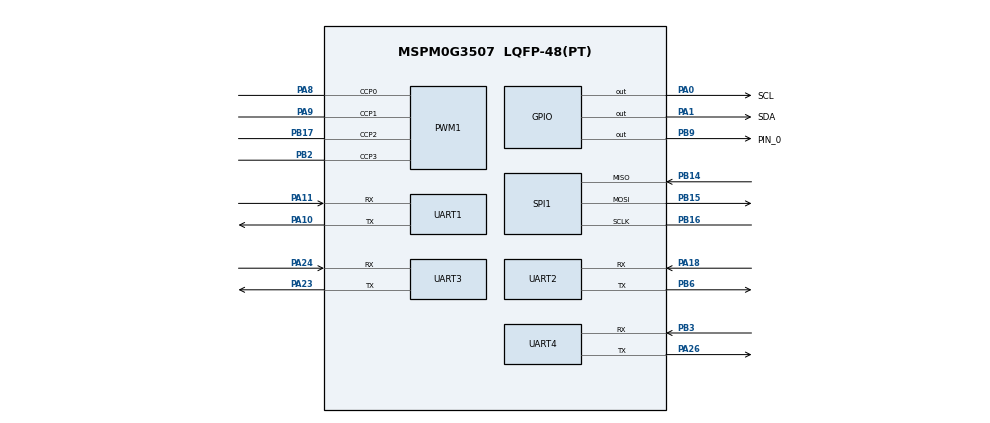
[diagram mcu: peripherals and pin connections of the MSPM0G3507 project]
/**
 * These arguments were used when this file was generated. They will be automatically applied on subsequent loads
 * via the GUI or CLI. Run CLI with '--help' for additional information on how to override these arguments.
 * @cliArgs --device "MSPM0G350X" --part "Default" --package "LQFP-48(PT)" --product "mspm0_sdk@2.10.00.04"
 * @v2CliArgs --device "MSPM0G3507" --package "LQFP-48(PT)" --product "mspm0_sdk@2.10.00.04"
 * @versions {"tool":"1.26.2+4477"}
 */

/**
 * Import the modules used in this configuration.
 */
const GPIO   = scripting.addModule("/ti/driverlib/GPIO", {}, false);
const GPIO1  = GPIO.addInstance();
const GPIO2  = GPIO.addInstance();
const GPIO3  = GPIO.addInstance();
const PWM    = scripting.addModule("/ti/driverlib/PWM", {}, false);
const PWM1   = PWM.addInstance();
const SPI    = scripting.addModule("/ti/driverlib/SPI", {}, false);
const SPI1   = SPI.addInstance();
const SYSCTL = scripting.addModule("/ti/driverlib/SYSCTL");
const TIMER  = scripting.addModule("/ti/driverlib/TIMER", {}, false);
const TIMER1 = TIMER.addInstance();
const UART   = scripting.addModule("/ti/driverlib/UART", {}, false);
const UART1  = UART.addInstance();
const UART2  = UART.addInstance();
const UART3  = UART.addInstance();
const UART4  = UART.addInstance();

/**
 * Write custom configuration values to the imported modules.
 */
const divider9       = system.clockTree["UDIV"];
divider9.divideValue = 2;

const gate7  = system.clockTree["MFCLKGATE"];
gate7.enable = true;

const multiplier2         = system.clockTree["PLL_QDIV"];
multiplier2.multiplyValue = 5;

const mux2       = system.clockTree["CANCLKMUX"];
mux2.inputSelect = "CANCLKMUX_PLLCLK1_OUT";

const mux4       = system.clockTree["EXHFMUX"];
mux4.inputSelect = "EXHFMUX_XTAL";

const mux8       = system.clockTree["HSCLKMUX"];
mux8.inputSelect = "HSCLKMUX_SYSPLL0";

const mux10       = system.clockTree["MFPCLKMUX"];
mux10.inputSelect = "MFPCLKMUX_HFCLK";

const pinFunction4       = system.clockTree["HFXT"];
pinFunction4.HFXTStartup = 10;
pinFunction4.enable      = true;
pinFunction4.inputFreq   = 8;

GPIO1.$name                              = "LED";
GPIO1.port                               = "PORTA";
GPIO1.associatedPins[0].internalResistor = "PULL_DOWN";
GPIO1.associatedPins[0].$name            = "A27";
GPIO1.associatedPins[0].assignedPin      = "27";

const Board = scripting.addModule("/ti/driverlib/Board", {}, false);

GPIO2.$name                              = "IIC";
GPIO2.associatedPins.create(2);
GPIO2.associatedPins[0].$name            = "SCL";
GPIO2.associatedPins[0].internalResistor = "PULL_UP";
GPIO2.associatedPins[0].initialValue     = "SET";
GPIO2.associatedPins[0].ioStructure      = "OD";
GPIO2.associatedPins[0].pin.$assign      = "PA0";
GPIO2.associatedPins[1].$name            = "SDA";
GPIO2.associatedPins[1].internalResistor = "PULL_UP";
GPIO2.associatedPins[1].initialValue     = "SET";
GPIO2.associatedPins[1].ioStructure      = "OD";
GPIO2.associatedPins[1].pin.$assign      = "PA1";

GPIO3.$name                          = "spi_cs";
GPIO3.associatedPins[0].$name        = "PIN_0";
GPIO3.associatedPins[0].assignedPort = "PORTB";
GPIO3.associatedPins[0].pin.$assign  = "PB9";

PWM1.$name                              = "PWM_MOTOR";
PWM1.timerStartTimer                    = true;
PWM1.ccIndex                            = [0,1,2,3];
PWM1.clockDivider                       = 4;
PWM1.pwmMode                            = "EDGE_ALIGN_UP";
PWM1.interrupts                         = ["LOAD_EVENT"];
PWM1.PWM_CHANNEL_0.$name                = "ti_driverlib_pwm_PWMTimerCC0";
PWM1.PWM_CHANNEL_0.dutyCycle            = 50;
PWM1.PWM_CHANNEL_1.$name                = "ti_driverlib_pwm_PWMTimerCC1";
PWM1.PWM_CHANNEL_1.dutyCycle            = 50;
PWM1.ccp0PinConfig.direction            = scripting.forceWrite("OUTPUT");
PWM1.ccp0PinConfig.hideOutputInversion  = scripting.forceWrite(false);
PWM1.ccp0PinConfig.onlyInternalResistor = scripting.forceWrite(false);
PWM1.ccp0PinConfig.passedPeripheralType = scripting.forceWrite("Digital");
PWM1.ccp0PinConfig.$name                = "ti_driverlib_gpio_GPIOPinGeneric2";
PWM1.ccp1PinConfig.direction            = scripting.forceWrite("OUTPUT");
PWM1.ccp1PinConfig.hideOutputInversion  = scripting.forceWrite(false);
PWM1.ccp1PinConfig.onlyInternalResistor = scripting.forceWrite(false);
PWM1.ccp1PinConfig.passedPeripheralType = scripting.forceWrite("Digital");
PWM1.ccp1PinConfig.$name                = "ti_driverlib_gpio_GPIOPinGeneric3";
PWM1.peripheral.$assign                 = "TIMA0";
PWM1.peripheral.ccp0Pin.$assign         = "PA8";
PWM1.peripheral.ccp1Pin.$assign         = "PA9";
PWM1.peripheral.ccp2Pin.$assign         = "PB17";
PWM1.peripheral.ccp3Pin.$assign         = "PB2";
PWM1.PWM_CHANNEL_2.$name                = "ti_driverlib_pwm_PWMTimerCC2";
PWM1.PWM_CHANNEL_2.dutyCycle            = 50;
PWM1.PWM_CHANNEL_3.$name                = "ti_driverlib_pwm_PWMTimerCC3";
PWM1.PWM_CHANNEL_3.dutyCycle            = 50;
PWM1.ccp2PinConfig.$name                = "ti_driverlib_gpio_GPIOPinGeneric5";
PWM1.ccp3PinConfig.$name                = "ti_driverlib_gpio_GPIOPinGeneric6";

SPI1.$name                                   = "SPI_0";
SPI1.peripheral.$assign                      = "SPI1";
SPI1.peripheral.sclkPin.$assign              = "PB16";
SPI1.peripheral.mosiPin.$assign              = "PB15";
SPI1.peripheral.misoPin.$assign              = "PB14";
SPI1.peripheral.cs0Pin.$assignAllowConflicts = "PA2";
SPI1.sclkPinConfig.$name                     = "ti_driverlib_gpio_GPIOPinGeneric10";
SPI1.mosiPinConfig.$name                     = "ti_driverlib_gpio_GPIOPinGeneric12";
SPI1.misoPinConfig.$name                     = "ti_driverlib_gpio_GPIOPinGeneric13";
SPI1.cs0PinConfig.$name                      = "ti_driverlib_gpio_GPIOPinGeneric14";

SYSCTL.forceDefaultClkConfig = true;
SYSCTL.clockTreeEn           = true;
SYSCTL.validateClkStatus     = true;

TIMER1.$name             = "TIMER_0";
TIMER1.interruptPriority = "3";
TIMER1.timerClkDiv       = 8;
TIMER1.timerClkPrescale  = 10;
TIMER1.timerPeriod       = "65.536ms";
TIMER1.timerMode         = "PERIODIC_UP";
TIMER1.interrupts        = ["LOAD"];

UART1.interruptPriority                = "3";
UART1.targetBaudRate                   = 115200;
UART1.$name                            = "UART_0_DEBUG";
UART1.enableFIFO                       = true;
UART1.enabledDMATXTriggers             = "DL_UART_DMA_INTERRUPT_TX";
UART1.rxFifoThreshold                  = "DL_UART_RX_FIFO_LEVEL_ONE_ENTRY";
UART1.enabledInterrupts                = ["DMA_DONE_TX","EOT_DONE","RX","RX_TIMEOUT_ERROR"];
UART1.enableDMARX                      = false;
UART1.rxTimeoutValue                   = 10;
UART1.peripheral.$assign               = "UART0";
UART1.peripheral.rxPin.$assign         = "PA11";
UART1.peripheral.txPin.$assign         = "PA10";
UART1.txPinConfig.direction            = scripting.forceWrite("OUTPUT");
UART1.txPinConfig.hideOutputInversion  = scripting.forceWrite(false);
UART1.txPinConfig.onlyInternalResistor = scripting.forceWrite(false);
UART1.txPinConfig.passedPeripheralType = scripting.forceWrite("Digital");
UART1.txPinConfig.$name                = "ti_driverlib_gpio_GPIOPinGeneric0";
UART1.rxPinConfig.hideOutputInversion  = scripting.forceWrite(false);
UART1.rxPinConfig.onlyInternalResistor = scripting.forceWrite(false);
UART1.rxPinConfig.passedPeripheralType = scripting.forceWrite("Digital");
UART1.rxPinConfig.$name                = "ti_driverlib_gpio_GPIOPinGeneric1";
UART1.DMA_CHANNEL_TX.$name             = "DMA_CH1";
UART1.DMA_CHANNEL_TX.srcLength         = "BYTE";
UART1.DMA_CHANNEL_TX.dstLength         = "BYTE";
UART1.DMA_CHANNEL_TX.addressMode       = "b2f";
UART1.DMA_CHANNEL_TX.enableInterrupt   = true;

UART2.targetBaudRate                    = 115200;
UART2.$name                             = "UART1";
UART2.enableFIFO                        = true;
UART2.rxFifoThreshold                   = "DL_UART_RX_FIFO_LEVEL_ONE_ENTRY";
UART2.rxTimeoutValue                    = 10;
UART2.enabledInterrupts                 = ["DMA_DONE_TX","EOT_DONE","RX"];
UART2.interruptPriority                 = "3";
UART2.enabledDMATXTriggers              = "DL_UART_DMA_INTERRUPT_TX";
UART2.peripheral.$assign                = "UART1";
UART2.peripheral.rxPin.$assign          = "PA18";
UART2.peripheral.txPin.$assign          = "PB6";
UART2.txPinConfig.direction             = scripting.forceWrite("OUTPUT");
UART2.txPinConfig.hideOutputInversion   = scripting.forceWrite(false);
UART2.txPinConfig.onlyInternalResistor  = scripting.forceWrite(false);
UART2.txPinConfig.passedPeripheralType  = scripting.forceWrite("Digital");
UART2.txPinConfig.$name                 = "ti_driverlib_gpio_GPIOPinGeneric19";
UART2.rxPinConfig.hideOutputInversion   = scripting.forceWrite(false);
UART2.rxPinConfig.onlyInternalResistor  = scripting.forceWrite(false);
UART2.rxPinConfig.passedPeripheralType  = scripting.forceWrite("Digital");
UART2.rxPinConfig.$name                 = "ti_driverlib_gpio_GPIOPinGeneric20";
UART2.DMA_CHANNEL_TX.$name              = "DMA_CH0";
UART2.DMA_CHANNEL_TX.addressMode        = "b2f";
UART2.DMA_CHANNEL_TX.srcLength          = "BYTE";
UART2.DMA_CHANNEL_TX.dstLength          = "BYTE";
UART2.DMA_CHANNEL_TX.enableInterrupt    = true;
UART2.DMA_CHANNEL_TX.peripheral.$assign = "DMA_CH1";

UART3.$name                             = "UART2";
UART3.enableFIFO                        = true;
UART3.rxFifoThreshold                   = "DL_UART_RX_FIFO_LEVEL_ONE_ENTRY";
UART3.rxTimeoutValue                    = 10;
UART3.enabledInterrupts                 = ["DMA_DONE_TX","EOT_DONE","RX"];
UART3.enabledDMATXTriggers              = "DL_UART_DMA_INTERRUPT_TX";
UART3.peripheral.rxPin.$assign          = "PA24";
UART3.peripheral.txPin.$assign          = "PA23";
UART3.txPinConfig.$name                 = "ti_driverlib_gpio_GPIOPinGeneric4";
UART3.txPinConfig.direction             = scripting.forceWrite("OUTPUT");
UART3.txPinConfig.hideOutputInversion   = scripting.forceWrite(false);
UART3.txPinConfig.onlyInternalResistor  = scripting.forceWrite(false);
UART3.txPinConfig.passedPeripheralType  = scripting.forceWrite("Digital");
UART3.rxPinConfig.$name                 = "ti_driverlib_gpio_GPIOPinGeneric7";
UART3.rxPinConfig.hideOutputInversion   = scripting.forceWrite(false);
UART3.rxPinConfig.onlyInternalResistor  = scripting.forceWrite(false);
UART3.rxPinConfig.passedPeripheralType  = scripting.forceWrite("Digital");
UART3.DMA_CHANNEL_TX.$name              = "DMA_CH2";
UART3.DMA_CHANNEL_TX.addressMode        = "b2f";
UART3.DMA_CHANNEL_TX.srcLength          = "BYTE";
UART3.DMA_CHANNEL_TX.dstLength          = "BYTE";
UART3.DMA_CHANNEL_TX.enableInterrupt    = true;
UART3.DMA_CHANNEL_TX.peripheral.$assign = "DMA_CH2";

UART4.$name                             = "UART3";
UART4.enabledDMATXTriggers              = "DL_UART_DMA_INTERRUPT_TX";
UART4.peripheral.rxPin.$assign          = "PB3";
UART4.peripheral.txPin.$assign          = "PA26";
UART4.txPinConfig.$name                 = "ti_driverlib_gpio_GPIOPinGeneric8";
UART4.txPinConfig.direction             = scripting.forceWrite("OUTPUT");
UART4.txPinConfig.hideOutputInversion   = scripting.forceWrite(false);
UART4.txPinConfig.onlyInternalResistor  = scripting.forceWrite(false);
UART4.txPinConfig.passedPeripheralType  = scripting.forceWrite("Digital");
UART4.rxPinConfig.$name                 = "ti_driverlib_gpio_GPIOPinGeneric9";
UART4.rxPinConfig.hideOutputInversion   = scripting.forceWrite(false);
UART4.rxPinConfig.onlyInternalResistor  = scripting.forceWrite(false);
UART4.rxPinConfig.passedPeripheralType  = scripting.forceWrite("Digital");
UART4.DMA_CHANNEL_TX.$name              = "DMA_CH3";
UART4.DMA_CHANNEL_TX.srcLength          = "BYTE";
UART4.DMA_CHANNEL_TX.addressMode        = "b2f";
UART4.DMA_CHANNEL_TX.dstLength          = "BYTE";
UART4.DMA_CHANNEL_TX.enableInterrupt    = true;
UART4.DMA_CHANNEL_TX.peripheral.$assign = "DMA_CH3";

const ProjectConfig              = scripting.addModule("/ti/project_config/ProjectConfig", {}, false);
ProjectConfig.migrationCondition = true;

/**
 * Pinmux solution for unlocked pins/peripherals. This ensures that minor changes to the automatic solver in a future
 * version of the tool will not impact the pinmux you originally saw.  These lines can be completely deleted in order to
 * re-solve from scratch.
 */
pinFunction4.peripheral.$suggestSolution           = "SYSCTL";
pinFunction4.peripheral.hfxInPin.$suggestSolution  = "PA5";
pinFunction4.peripheral.hfxOutPin.$suggestSolution = "PA6";
GPIO1.associatedPins[0].pin.$suggestSolution       = "PA27";
Board.peripheral.$suggestSolution                  = "DEBUGSS";
Board.peripheral.swclkPin.$suggestSolution         = "PA20";
Board.peripheral.swdioPin.$suggestSolution         = "PA19";
TIMER1.peripheral.$suggestSolution                 = "TIMA1";
UART1.DMA_CHANNEL_TX.peripheral.$suggestSolution   = "DMA_CH0";
UART3.peripheral.$suggestSolution                  = "UART2";
UART4.peripheral.$suggestSolution                  = "UART3";
